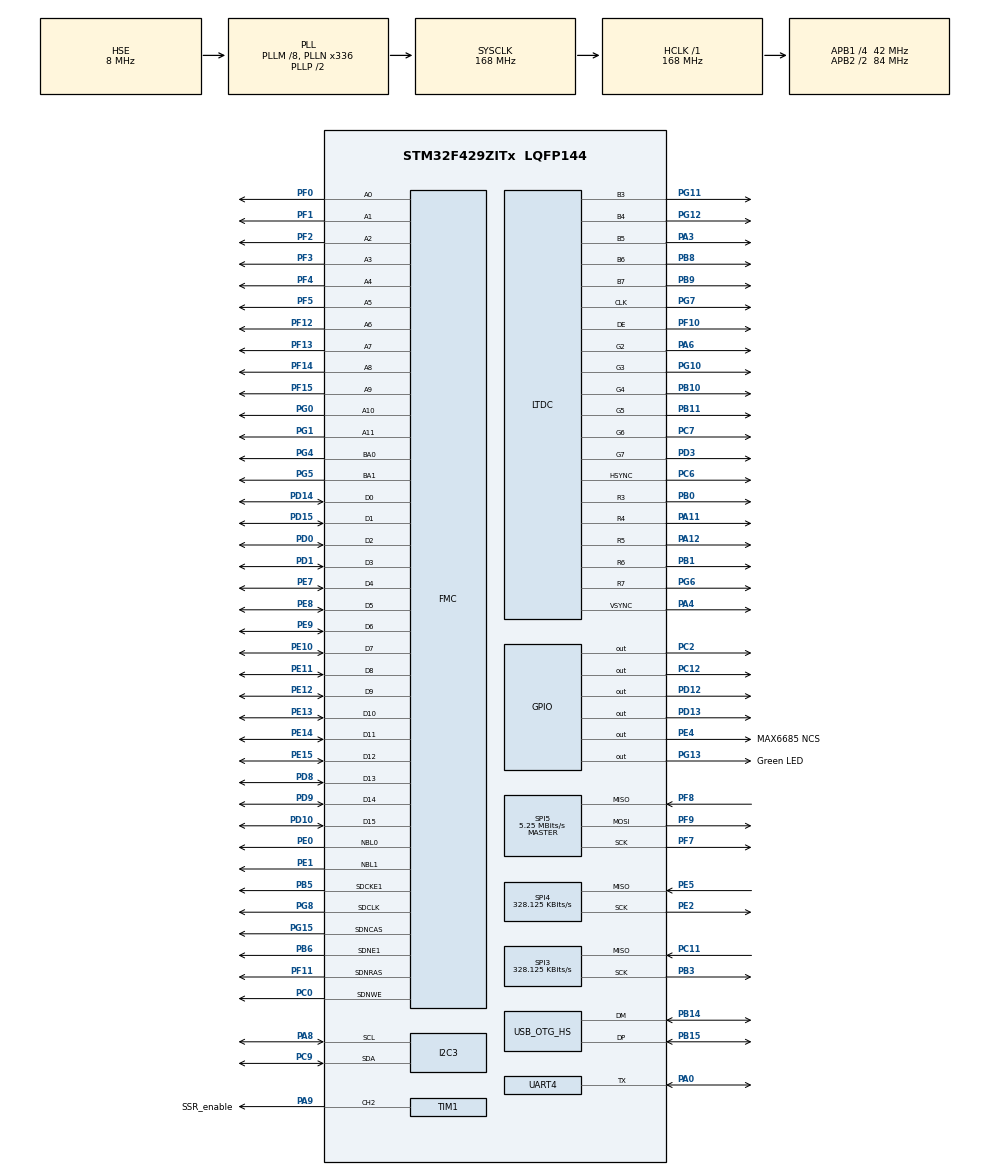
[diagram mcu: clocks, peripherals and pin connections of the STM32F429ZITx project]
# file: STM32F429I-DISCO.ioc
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PA11.GPIO_Speed=GPIO_SPEED_FREQ_HIGH
SH.FMC_D7_DA7.0=FMC_D7,sd-16b-d1
VP_SYS_VS_tim6.Mode=TIM6
SPI3.Direction=SPI_DIRECTION_2LINES_RXONLY
SPI4.VirtualType=VM_MASTER
SPI3.VirtualType=VM_MASTER
FMC.RCDDelay1=2
FMC.SDClockPeriod1=FMC_SDRAM_CLOCK_PERIOD_2
SH.FMC_A0.0=FMC_A0,12b-sda1
PB10.Mode=RGB565
NVIC.TIM6_DAC_IRQn=true\:0\:0\:false\:false\:true\:false\:false\:true
PG4.Signal=FMC_A14_BA0
PG8.Signal=FMC_SDCLK
PC12.Signal=GPIO_Output
PG0.Signal=FMC_A10
FMC.LoadToActiveDelay1=2
SH.FMC_D5_DA5.0=FMC_D5,sd-16b-d1
PA3.GPIO_Speed=GPIO_SPEED_FREQ_HIGH
PD3.GPIO_Speed=GPIO_SPEED_FREQ_HIGH
PG6.Mode=RGB565
PG13.Signal=GPIO_Output
RCC.SYSCLKSource=RCC_SYSCLKSOURCE_PLLCLK
PB11.GPIO_Speed=GPIO_SPEED_FREQ_HIGH
SH.FMC_A15_BA1.0=FMC_BA1,FourSdramBanks1
SH.FMC_D9_DA9.0=FMC_D9,sd-16b-d1
PA4.Mode=RGB565
PF7.Signal=SPI5_SCK
NVIC.DMA2D_IRQn=true\:5\:0\:true\:false\:true\:true\:true\:true
SH.FMC_SDNWE.0=FMC_SDNWE,12b-sda1
SH.FMC_D11_DA11.0=FMC_D11,sd-16b-d1
PE2.Mode=RX_Only_Simplex_Unidirect_Master
RCC.APB2TimFreq_Value=168000000
PB6.Signal=FMC_SDNE1
PC7.Signal=LTDC_G6
PH1/OSC_OUT.Signal=RCC_OSC_OUT
PB6.Mode=SdramChipSelect2_1
PD0.Signal=FMC_D2_DA2
PD8.Signal=FMC_D13_DA13
PE5.Signal=SPI4_MISO
PE1.Signal=FMC_NBL1
I2C3.Analog_Filter=I2C_ANALOGFILTER_DISABLE
PB3.Mode=RX_Only_Simplex_Unidirect_Master
FMC.SelfRefreshTime1=4
LTDC.PixelFormat_L0=LTDC_PIXEL_FORMAT_RGB565
PE9.Signal=FMC_D6_DA6
PB1.GPIO_Speed=GPIO_SPEED_FREQ_HIGH
SH.FMC_A2.0=FMC_A2,12b-sda1
PB14.Mode=Device_Only_FS
STMicroelectronics.X-CUBE-TOUCHGFX.4.16.1.tgfx_display_interface=disp_ltdc
PE4.GPIO_Label=MAX6685 NCS
PC9.Mode=I2C
PE2.Signal=SPI4_SCK
PF8.Mode=Full_Duplex_Master
PA8.Signal=I2C3_SCL
SH.FMC_D1_DA1.0=FMC_D1,sd-16b-d1
PF3.Signal=FMC_A3
PD3.Mode=RGB565
PE10.Signal=FMC_D7_DA7
LTDC.HSync=10
Mcu.Package=LQFP144
PB9.Signal=LTDC_B7
PB1.Signal=LTDC_R6
NVIC.TimeBase=TIM6_DAC_IRQn
SPI3.Mode=SPI_MODE_MASTER
PD12.Signal=GPIO_Output
STMicroelectronics.X-CUBE-TOUCHGFX.4.16.1.ApplicationCcGraphicsJjApplication=TouchGFXOoGenerator
NVIC.TimeBaseIP=TIM6
FMC.WriteRecoveryTime1=3
PC11.Mode=RX_Only_Simplex_Unidirect_Master
SH.FMC_A1.0=FMC_A1,12b-sda1
SPI5.CalculateBaudRate=5.25 MBits/s
RCC.APB2CLKDivider=RCC_HCLK_DIV2
SH.FMC_SDCLK.0=FMC_SDCLK,12b-sda1
LTDC.VSync=2
PF14.Signal=FMC_A8
RCC.APB1TimFreq_Value=84000000
VP_DMA2D_VS_DMA2D.Mode=DMA2D_Activate
PF10.Mode=RGB565
FMC.RowCycleDelay1=7
PA6.GPIO_Speed=GPIO_SPEED_FREQ_HIGH
PC6.GPIO_Speed=GPIO_SPEED_FREQ_HIGH
PD15.Signal=FMC_D1_DA1
SH.FMC_D3_DA3.0=FMC_D3,sd-16b-d1
SPI5.VirtualType=VM_MASTER
PG6.GPIO_Speed=GPIO_SPEED_FREQ_HIGH
PG12.Signal=LTDC_B4
VP_STMicroelectronics.X-CUBE-TOUCHGFX_VS_GraphicsJjApplication_4.16.1.Mode=GraphicsJjApplication
STMicroelectronics.X-CUBE-TOUCHGFX.4.16.1.tgfx_custom_height=240
SPI4.TIMode=SPI_TIMODE_DISABLE
SH.FMC_A4.0=FMC_A4,12b-sda1
FREERTOS.Tasks01=GUI_Task,24,8192,TouchGFX_Task,As weak,NULL,Dynamic,NULL,NULL
STMicroelectronics.X-CUBE-TOUCHGFX.4.16.1.tgfx_address1=0xd0000000
PG5.Signal=FMC_A15_BA1
PA9.GPIO_Label=SSR_enable
SH.FMC_D10_DA10.0=FMC_D10,sd-16b-d1
PD3.Signal=LTDC_G7
PC6.Signal=LTDC_HSYNC
PC2.Signal=GPIO_Output
PD1.Signal=FMC_D3_DA3
PC0.Signal=FMC_SDNWE
RCC.APB1CLKDivider=RCC_HCLK_DIV4
UART4.VirtualMode=Asynchronous
USB_OTG_HS.VirtualMode-Device_Only_FS=Device_Only_FS
PG13.GPIO_Label=Green LED
PG10.Signal=LTDC_G3
LTDC.ImageWidth_L0=240
PD10.Signal=FMC_D15_DA15
PA3.Mode=RGB565
TIM1.AutoReloadPreload=TIM_AUTORELOAD_PRELOAD_ENABLE
SH.FMC_A3.0=FMC_A3,12b-sda1
FMC.CASLatency1=FMC_SDRAM_CAS_LATENCY_3
PB11.Mode=RGB565
FREERTOS.configMAX_PRIORITIES=56
SH.FMC_D15_DA15.0=FMC_D15,sd-16b-d1
PC6.Mode=RGB565
PA9.Signal=S_TIM1_CH2
TIM1.Channel-PWM\ Generation2\ CH2=TIM_CHANNEL_2
PA0/WKUP.Mode=Half_duplex(single_wire_mode)
PB10.Signal=LTDC_G4
PB14.Signal=USB_OTG_HS_DM
PE2.GPIO_PuPd=GPIO_PULLDOWN
SH.FMC_A6.0=FMC_A6,12b-sda1
PE14.Signal=FMC_D11_DA11
LTDC.Blue_L0=0
PE15.Signal=FMC_D12_DA12
PE8.Signal=FMC_D5_DA5
PF13.Signal=FMC_A7
SH.FMC_SDNCAS.0=FMC_SDNCAS,12b-sda1
PA4.Signal=LTDC_VSYNC
PB5.Signal=FMC_SDCKE1
SH.FMC_A5.0=FMC_A5,12b-sda1
PG11.Mode=RGB565
LTDC.Alpha_L0=255
PA11.Signal=LTDC_R4
ProjectManager.HeapSize=0xB00
PB1.Mode=RGB565
PG12.GPIO_Speed=GPIO_SPEED_FREQ_HIGH
PF9.Signal=SPI5_MOSI
NVIC.PriorityGroup=NVIC_PRIORITYGROUP_4
PB8.Mode=RGB565
PA8.Mode=I2C
PF4.Signal=FMC_A4
PB0.Signal=LTDC_R3
Mcu.Family=STM32F4
LTDC.BlendingFactor1_L0=LTDC_BLENDING_FACTOR1_CA
NVIC.OTG_HS_IRQn=true\:5\:0\:false\:false\:true\:true\:false\:true
PA6.Mode=RGB565
SH.FMC_A8.0=FMC_A8,12b-sda1
VP_USB_DEVICE_VS_USB_DEVICE_CDC_HS.Mode=CDC_HS
RCC.CortexFreq_Value=168000000
PG6.Signal=LTDC_R7
PB10.GPIO_Speed=GPIO_SPEED_FREQ_HIGH
RCC.PLLSAIDivR=RCC_PLLSAIDIVR_8
SH.FMC_D14_DA14.0=FMC_D14,sd-16b-d1
TIM1.RepetitionCounter=255
LTDC.HBP=20
STMicroelectronics.X-CUBE-TOUCHGFX.4.16.1.tgfx_buffering_strategy=Double
SPI4.Direction=SPI_DIRECTION_2LINES_RXONLY
SH.FMC_NBL0.0=FMC_NBL0,Sd2ByteEnable1
SH.FMC_D6_DA6.0=FMC_D6,sd-16b-d1
PA11.Mode=RGB565
PA0/WKUP.Signal=UART4_TX
PC2.GPIO_Speed=GPIO_SPEED_FREQ_HIGH
SH.FMC_A14_BA0.0=FMC_BA0,FourSdramBanks1
SH.FMC_A11.0=FMC_A11,12b-sda1
PB11.Signal=LTDC_G5
PB15.Signal=USB_OTG_HS_DP
STMicroelectronics.X-CUBE-TOUCHGFX.4.16.1.tgfx_location=Allocate
PG11.Signal=LTDC_B3
PG15.Signal=FMC_SDNCAS
ProjectManager.StackSize=0xA00
VP_FREERTOS_VS_CMSIS_V2.Mode=CMSIS_V2
PD13.Signal=GPIO_Output
PC11.GPIO_PuPd=GPIO_PULLDOWN
SH.FMC_A7.0=FMC_A7,12b-sda1
PA12.Signal=LTDC_R5
TIM1.Prescaler=1200
SPI4.Mode=SPI_MODE_MASTER
PE5.GPIO_PuPd=GPIO_PULLDOWN
SPI3.CLKPolarity=SPI_POLARITY_LOW
PH0/OSC_IN.Mode=HSE-External-Oscillator
RCC.HCLKFreq_Value=168000000
SH.FMC_NBL1.0=FMC_NBL1,Sd2ByteEnable1
LTDC.WindowX1_L0=240
PF12.Signal=FMC_A6
SPI5.CLKPolarity=SPI_POLARITY_LOW
USB_DEVICE.VirtualMode-CDC_HS=Cdc
SH.FMC_A10.0=FMC_A10,12b-sda1
RCC.AHBFreq_Value=168000000
SPI3.DataSize=SPI_DATASIZE_16BIT
RCC.HSE_VALUE=8000000
USB_OTG_HS.lpm_enable-Device_Only_FS=DISABLE
SH.FMC_D8_DA8.0=FMC_D8,sd-16b-d1
FMC.ExitSelfRefreshDelay1=7
FMC.RPDelay1=2
PA4.GPIO_Speed=GPIO_SPEED_FREQ_HIGH
SH.FMC_D2_DA2.0=FMC_D2,sd-16b-d1
PG11.GPIO_Speed=GPIO_SPEED_FREQ_HIGH
PB3.GPIO_PuPd=GPIO_PULLDOWN
PF9.Mode=Full_Duplex_Master
PE13.Signal=FMC_D10_DA10
PF11.Signal=FMC_SDNRAS
PB5.Mode=SdramChipSelect2_1
LTDC.HFP=10
LTDC.BlendingFactor2_L0=LTDC_BLENDING_FACTOR2_CA
FMC.ReadPipeDelay1=FMC_SDRAM_RPIPE_DELAY_1
SH.FMC_SDNRAS.0=FMC_SDNRAS,12b-sda1
DMA2D.ColorMode=DMA2D_OUTPUT_RGB565
LTDC.ActiveW=240
PH1/OSC_OUT.Mode=HSE-External-Oscillator
PE4.Signal=GPIO_Output
SPI4.BaudRatePrescaler=SPI_BAUDRATEPRESCALER_256
FREERTOS.configTOTAL_HEAP_SIZE=65536
SPI5.BaudRatePrescaler=SPI_BAUDRATEPRESCALER_16
PA6.Signal=LTDC_G2
SH.FMC_D0_DA0.0=FMC_D0,sd-16b-d1
TIM1.Pulse-PWM\ Generation2\ CH2=12000
SH.FMC_A9.0=FMC_A9,12b-sda1
USB_DEVICE.CLASS_NAME_HS=CDC
PF8.Signal=SPI5_MISO
SH.FMC_D4_DA4.0=FMC_D4,sd-16b-d1
RCC.PLLSAIN=192
PF5.Signal=FMC_A5
RCC.PLLSAIR=4
USB_DEVICE.VirtualModeHS=Cdc_HS
PB9.GPIO_Speed=GPIO_SPEED_FREQ_HIGH
PF0.Signal=FMC_A0
PE7.Signal=FMC_D4_DA4
USB_OTG_HS.dma_enable-Device_Only_FS=DISABLE
PA12.GPIO_Speed=GPIO_SPEED_FREQ_HIGH
STMicroelectronics.X-CUBE-TOUCHGFX.4.16.1.tgfx_vsync=vsync_ltdc
PA3.Signal=LTDC_B5
NVIC.LTDC_IRQn=true\:5\:0\:true\:false\:true\:true\:true\:true
LTDC.VFP=4
PD12.GPIO_Speed=GPIO_SPEED_FREQ_HIGH
LTDC.WindowY1_L0=320
PG7.Signal=LTDC_CLK
SPI4.DataSize=SPI_DATASIZE_16BIT
PG1.Signal=FMC_A11
PC11.Signal=SPI3_MISO
PF10.GPIO_Speed=GPIO_SPEED_FREQ_HIGH
PG10.Mode=RGB565
USB_OTG_HS.Sof_enable-Device_Only_FS=DISABLE
PD9.Signal=FMC_D14_DA14
FREERTOS.configUSE_APPLICATION_TASK_TAG=1
PA9.GPIO_PuPd=GPIO_PULLDOWN
PG10.GPIO_Speed=GPIO_SPEED_FREQ_HIGH
SPI5.Mode=SPI_MODE_MASTER
TIM1.ClockDivision=TIM_CLOCKDIVISION_DIV4
USB_OTG_HS.low_power_enable-Device_Only_FS=DISABLE
PB0.GPIO_Speed=GPIO_SPEED_FREQ_HIGH
PF7.Mode=Full_Duplex_Master
STMicroelectronics.X-CUBE-TOUCHGFX.4.16.1.tgfx_hardware_accelerator=dma_2d
ProjectManager.TargetToolchain=STM32CubeIDE
SH.FMC_D13_DA13.0=FMC_D13,sd-16b-d1
LTDC.ActiveH=320
PB9.Mode=RGB565
PF2.Signal=FMC_A2
PE11.Signal=FMC_D8_DA8
PG7.Mode=RGB565
RCC.LSE_VALUE=32768
PB0.Mode=RGB565
board=custom
PG12.Mode=RGB565
SPI3.CLKPhase=SPI_PHASE_1EDGE
USB_OTG_HS.use_dedicated_ep1-Device_Only_FS=DISABLE
PC7.GPIO_Speed=GPIO_SPEED_FREQ_HIGH
RCC.VCOOutputFreq_Value=336000000
PB15.Mode=Device_Only_FS
NVIC.OTG_HS_EP1_OUT_IRQn=true\:5\:0\:false\:false\:true\:true\:false\:true
PH0/OSC_IN.Signal=RCC_OSC_IN
PG7.GPIO_Speed=GPIO_SPEED_FREQ_HIGH
RCC.APB2Freq_Value=84000000
SPI3.CalculateBaudRate=328.125 KBits/s
LTDC.Layers=0
SH.S_TIM1_CH2.0=TIM1_CH2,PWM Generation2 CH2
PF10.Signal=LTDC_DE
PE5.Mode=RX_Only_Simplex_Unidirect_Master
SPI3.BaudRatePrescaler=SPI_BAUDRATEPRESCALER_128
SH.FMC_D12_DA12.0=FMC_D12,sd-16b-d1
PF15.Signal=FMC_A9
SPI4.CalculateBaudRate=328.125 KBits/s
PF1.Signal=FMC_A1
Mcu.Name=STM32F429ZITx
PE0.Signal=FMC_NBL0
PE12.Signal=FMC_D9_DA9
NVIC.OTG_HS_EP1_IN_IRQn=true\:5\:0\:false\:false\:true\:true\:false\:true
PD14.Signal=FMC_D0_DA0
RCC.48MHZClocksFreq_Value=48000000
PB3.Signal=SPI3_SCK
RCC.SYSCLKFreq_VALUE=168000000
PA12.Mode=RGB565
SPI5.CRCCalculation=SPI_CRCCALCULATION_DISABLE
RCC.HSI_VALUE=16000000
RCC.PLLQ=7
RCC.PLLM=8
RCC.PLLN=336
PB8.Signal=LTDC_B6
PC9.Signal=I2C3_SDA
PC7.Mode=RGB565
RCC.APB1Freq_Value=42000000
PB8.GPIO_Speed=GPIO_SPEED_FREQ_HIGH
VP_CRC_VS_CRC.Mode=CRC_Activate
LTDC.ImageHeight_L0=320
TIM1.TIM_MasterSlaveMode=TIM_MASTERSLAVEMODE_ENABLE
SPI5.Direction=SPI_DIRECTION_2LINES

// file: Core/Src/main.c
/* USER CODE BEGIN Header */
/**
  ******************************************************************************
  * @file           : main.c
  * @brief          : Main program body
  ******************************************************************************
  * @attention
  *
  * <h2><center>&copy; Copyright (c) 2020 STMicroelectronics.
  * All rights reserved.</center></h2>
  *
  * This software component is licensed by ST under Ultimate Liberty license
  * SLA0044, the "License"; You may not use this file except in compliance with
  * the License. You may obtain a copy of the License at:
  *                             www.st.com/SLA0044
  *
  ******************************************************************************
  */
/* USER CODE END Header */
#include "main.h"
#include "cmsis_os.h"
#include "app_touchgfx.h"
#include "usb_device.h"

/* USER CODE BEGIN Includes */
#include <stdio.h>
#include "Components/ili9341/ili9341.h"
#include "common.h"
/* USER CODE END Includes */

/* USER CODE BEGIN PD */
#define REFRESH_COUNT           ((uint32_t)1386)   /* SDRAM refresh counter */
#define SDRAM_TIMEOUT           ((uint32_t)0xFFFF)

/**
  * @brief  FMC SDRAM Mode definition register defines
  */
#define SDRAM_MODEREG_BURST_LENGTH_1             ((uint16_t)0x0000)
#define SDRAM_MODEREG_BURST_LENGTH_2             ((uint16_t)0x0001)
#define SDRAM_MODEREG_BURST_LENGTH_4             ((uint16_t)0x0002)
#define SDRAM_MODEREG_BURST_LENGTH_8             ((uint16_t)0x0004)
#define SDRAM_MODEREG_BURST_TYPE_SEQUENTIAL      ((uint16_t)0x0000)
#define SDRAM_MODEREG_BURST_TYPE_INTERLEAVED     ((uint16_t)0x0008)
#define SDRAM_MODEREG_CAS_LATENCY_2              ((uint16_t)0x0020)
#define SDRAM_MODEREG_CAS_LATENCY_3              ((uint16_t)0x0030)
#define SDRAM_MODEREG_OPERATING_MODE_STANDARD    ((uint16_t)0x0000)
#define SDRAM_MODEREG_WRITEBURST_MODE_PROGRAMMED ((uint16_t)0x0000)
#define SDRAM_MODEREG_WRITEBURST_MODE_SINGLE     ((uint16_t)0x0200)

#define I2C3_TIMEOUT_MAX                    0x3000 /*<! The value of the maximal timeout for I2C waiting loops */
#define SPI5_TIMEOUT_MAX                    0x1000
/* USER CODE END PD */

CRC_HandleTypeDef hcrc;

DMA2D_HandleTypeDef hdma2d;

I2C_HandleTypeDef hi2c3;

LTDC_HandleTypeDef hltdc;

SPI_HandleTypeDef hspi3;
SPI_HandleTypeDef hspi4;
SPI_HandleTypeDef hspi5;

TIM_HandleTypeDef htim1;

UART_HandleTypeDef huart4;

SDRAM_HandleTypeDef hsdram1;

/* Definitions for GUI_Task */
osThreadId_t GUI_TaskHandle;
const osThreadAttr_t GUI_Task_attributes = {
  .name = "GUI_Task",
  .stack_size = 8192 * 4,
  .priority = (osPriority_t) osPriorityNormal,
};
/* USER CODE BEGIN PV */
osThreadId_t App_TaskHandle;
const osThreadAttr_t App_Task_attributes = {
  .name = "App_Task",
  .stack_size = 8192 * 1,
  .priority = (osPriority_t) osPriorityNormal,
};

/* USER CODE END PV */

void SystemClock_Config(void);
static void MX_GPIO_Init(void);
static void MX_CRC_Init(void);
static void MX_I2C3_Init(void);
static void MX_SPI5_Init(void);
static void MX_FMC_Init(void);
static void MX_LTDC_Init(void);
static void MX_DMA2D_Init(void);
static void MX_SPI4_Init(void);
static void MX_TIM1_Init(void);
static void MX_SPI3_Init(void);
static void MX_UART4_Init(void);
void TouchGFX_Task(void *argument);

/* USER CODE BEGIN PFP */
void App_Task(void *argument);

osMessageQueueId_t TempQueue;
osEventFlagsId_t msgFlags;

static void BSP_SDRAM_Initialization_Sequence(SDRAM_HandleTypeDef *hsdram, FMC_SDRAM_CommandTypeDef *Command);

static uint8_t            I2C3_ReadData(uint8_t Addr, uint8_t Reg);
static void               I2C3_WriteData(uint8_t Addr, uint8_t Reg, uint8_t Value);
static uint8_t            I2C3_ReadBuffer(uint8_t Addr, uint8_t Reg, uint8_t *pBuffer, uint16_t Length);

/* SPIx bus function */
static void               SPI5_Write(uint16_t Value);
static uint32_t           SPI5_Read(uint8_t ReadSize);
static void               SPI5_Error(void);

/* Link function for LCD peripheral */
void                      LCD_IO_Init(void);
void                      LCD_IO_WriteData(uint16_t RegValue);
void                      LCD_IO_WriteReg(uint8_t Reg);
uint32_t                  LCD_IO_ReadData(uint16_t RegValue, uint8_t ReadSize);
void                      LCD_Delay(uint32_t delay);

/* IOExpander IO functions */
void                      IOE_Init(void);
void                      IOE_ITConfig(void);
void                      IOE_Delay(uint32_t Delay);
void                      IOE_Write(uint8_t Addr, uint8_t Reg, uint8_t Value);
uint8_t                   IOE_Read(uint8_t Addr, uint8_t Reg);
uint16_t                  IOE_ReadMultiple(uint8_t Addr, uint8_t Reg, uint8_t *pBuffer, uint16_t Length);

/* USER CODE END PFP */

/* USER CODE BEGIN 0 */
static LCD_DrvTypeDef* LcdDrv;

uint32_t I2c3Timeout = I2C3_TIMEOUT_MAX; /*<! Value of Timeout when I2C communication fails */
uint32_t Spi5Timeout = SPI5_TIMEOUT_MAX; /*<! Value of Timeout when SPI communication fails */
/* USER CODE END 0 */

int main(void)
{

  /* MCU Configuration--------------------------------------------------------*/

  /* Reset of all peripherals, Initializes the Flash interface and the Systick. */
  HAL_Init();

  /* Configure the system clock */
  SystemClock_Config();

  /* Initialize all configured peripherals */
  MX_GPIO_Init();
  MX_CRC_Init();
  MX_I2C3_Init();
  MX_SPI5_Init();
  MX_FMC_Init();
  MX_LTDC_Init();
  MX_DMA2D_Init();
  MX_SPI4_Init();
  MX_TIM1_Init();
  MX_SPI3_Init();
  MX_UART4_Init();
  MX_TouchGFX_Init();
  /* USER CODE BEGIN 2 */
  TempQueue = osMessageQueueNew(1, sizeof(float), NULL);
  msgFlags =  osEventFlagsNew(NULL);

  HAL_GPIO_WritePin(GPIOE, GPIO_PIN_4, GPIO_PIN_SET);
  /* USER CODE END 2 */

  /* Init scheduler */
  osKernelInitialize();

  /* Create the thread(s) */
  /* creation of GUI_Task */
  GUI_TaskHandle = osThreadNew(TouchGFX_Task, NULL, &GUI_Task_attributes);

  /* USER CODE BEGIN RTOS_THREADS */
  /* add threads, ... */
  App_TaskHandle = osThreadNew(App_Task, NULL, &App_Task_attributes);
  /* USER CODE END RTOS_THREADS */

  /* Start scheduler */
  osKernelStart();

  /* We should never get here as control is now taken by the scheduler */
  /* Infinite loop */
  while (1)
  {

  }
}

void SystemClock_Config(void)
{
  RCC_OscInitTypeDef RCC_OscInitStruct = {0};
  RCC_ClkInitTypeDef RCC_ClkInitStruct = {0};
  RCC_PeriphCLKInitTypeDef PeriphClkInitStruct = {0};

  /** Configure the main internal regulator output voltage
  */
  __HAL_RCC_PWR_CLK_ENABLE();
  __HAL_PWR_VOLTAGESCALING_CONFIG(PWR_REGULATOR_VOLTAGE_SCALE1);
  /** Initializes the RCC Oscillators according to the specified parameters
  * in the RCC_OscInitTypeDef structure.
  */
  RCC_OscInitStruct.OscillatorType = RCC_OSCILLATORTYPE_HSE;
  RCC_OscInitStruct.HSEState = RCC_HSE_ON;
  RCC_OscInitStruct.PLL.PLLState = RCC_PLL_ON;
  RCC_OscInitStruct.PLL.PLLSource = RCC_PLLSOURCE_HSE;
  RCC_OscInitStruct.PLL.PLLM = 8;
  RCC_OscInitStruct.PLL.PLLN = 336;
  RCC_OscInitStruct.PLL.PLLP = RCC_PLLP_DIV2;
  RCC_OscInitStruct.PLL.PLLQ = 7;
  if (HAL_RCC_OscConfig(&RCC_OscInitStruct) != HAL_OK)
  {
    Error_Handler();
  }
  /** Initializes the CPU, AHB and APB buses clocks
  */
  RCC_ClkInitStruct.ClockType = RCC_CLOCKTYPE_HCLK|RCC_CLOCKTYPE_SYSCLK
                              |RCC_CLOCKTYPE_PCLK1|RCC_CLOCKTYPE_PCLK2;
  RCC_ClkInitStruct.SYSCLKSource = RCC_SYSCLKSOURCE_PLLCLK;
  RCC_ClkInitStruct.AHBCLKDivider = RCC_SYSCLK_DIV1;
  RCC_ClkInitStruct.APB1CLKDivider = RCC_HCLK_DIV4;
  RCC_ClkInitStruct.APB2CLKDivider = RCC_HCLK_DIV2;

  if (HAL_RCC_ClockConfig(&RCC_ClkInitStruct, FLASH_LATENCY_5) != HAL_OK)
  {
    Error_Handler();
  }
  PeriphClkInitStruct.PeriphClockSelection = RCC_PERIPHCLK_LTDC;
  PeriphClkInitStruct.PLLSAI.PLLSAIN = 192;
  PeriphClkInitStruct.PLLSAI.PLLSAIR = 4;
  PeriphClkInitStruct.PLLSAIDivR = RCC_PLLSAIDIVR_8;
  if (HAL_RCCEx_PeriphCLKConfig(&PeriphClkInitStruct) != HAL_OK)
  {
    Error_Handler();
  }
}

static void MX_CRC_Init(void)
{

  hcrc.Instance = CRC;
  if (HAL_CRC_Init(&hcrc) != HAL_OK)
  {
    Error_Handler();
  }

}

static void MX_DMA2D_Init(void)
{

  hdma2d.Instance = DMA2D;
  hdma2d.Init.Mode = DMA2D_M2M;
  hdma2d.Init.ColorMode = DMA2D_OUTPUT_RGB565;
  hdma2d.Init.OutputOffset = 0;
  hdma2d.LayerCfg[1].InputOffset = 0;
  hdma2d.LayerCfg[1].InputColorMode = DMA2D_INPUT_RGB565;
  hdma2d.LayerCfg[1].AlphaMode = DMA2D_NO_MODIF_ALPHA;
  hdma2d.LayerCfg[1].InputAlpha = 0;
  if (HAL_DMA2D_Init(&hdma2d) != HAL_OK)
  {
    Error_Handler();
  }
  if (HAL_DMA2D_ConfigLayer(&hdma2d, 1) != HAL_OK)
  {
    Error_Handler();
  }

}

static void MX_I2C3_Init(void)
{

  hi2c3.Instance = I2C3;
  hi2c3.Init.ClockSpeed = 100000;
  hi2c3.Init.DutyCycle = I2C_DUTYCYCLE_2;
  hi2c3.Init.OwnAddress1 = 0;
  hi2c3.Init.AddressingMode = I2C_ADDRESSINGMODE_7BIT;
  hi2c3.Init.DualAddressMode = I2C_DUALADDRESS_DISABLE;
  hi2c3.Init.OwnAddress2 = 0;
  hi2c3.Init.GeneralCallMode = I2C_GENERALCALL_DISABLE;
  hi2c3.Init.NoStretchMode = I2C_NOSTRETCH_DISABLE;
  if (HAL_I2C_Init(&hi2c3) != HAL_OK)
  {
    Error_Handler();
  }
  /** Configure Analogue filter
  */
  if (HAL_I2CEx_ConfigAnalogFilter(&hi2c3, I2C_ANALOGFILTER_DISABLE) != HAL_OK)
  {
    Error_Handler();
  }
  /** Configure Digital filter
  */
  if (HAL_I2CEx_ConfigDigitalFilter(&hi2c3, 0) != HAL_OK)
  {
    Error_Handler();
  }

}

static void MX_LTDC_Init(void)
{

  LTDC_LayerCfgTypeDef pLayerCfg = {0};

  hltdc.Instance = LTDC;
  hltdc.Init.HSPolarity = LTDC_HSPOLARITY_AL;
  hltdc.Init.VSPolarity = LTDC_VSPOLARITY_AL;
  hltdc.Init.DEPolarity = LTDC_DEPOLARITY_AL;
  hltdc.Init.PCPolarity = LTDC_PCPOLARITY_IPC;
  hltdc.Init.HorizontalSync = 9;
  hltdc.Init.VerticalSync = 1;
  hltdc.Init.AccumulatedHBP = 29;
  hltdc.Init.AccumulatedVBP = 3;
  hltdc.Init.AccumulatedActiveW = 269;
  hltdc.Init.AccumulatedActiveH = 323;
  hltdc.Init.TotalWidth = 279;
  hltdc.Init.TotalHeigh = 327;
  hltdc.Init.Backcolor.Blue = 0;
  hltdc.Init.Backcolor.Green = 0;
  hltdc.Init.Backcolor.Red = 0;
  if (HAL_LTDC_Init(&hltdc) != HAL_OK)
  {
    Error_Handler();
  }
  pLayerCfg.WindowX0 = 0;
  pLayerCfg.WindowX1 = 240;
  pLayerCfg.WindowY0 = 0;
  pLayerCfg.WindowY1 = 320;
  pLayerCfg.PixelFormat = LTDC_PIXEL_FORMAT_RGB565;
  pLayerCfg.Alpha = 255;
  pLayerCfg.Alpha0 = 0;
  pLayerCfg.BlendingFactor1 = LTDC_BLENDING_FACTOR1_CA;
  pLayerCfg.BlendingFactor2 = LTDC_BLENDING_FACTOR2_CA;
  pLayerCfg.FBStartAdress = 0;
  pLayerCfg.ImageWidth = 240;
  pLayerCfg.ImageHeight = 320;
  pLayerCfg.Backcolor.Blue = 0;
  pLayerCfg.Backcolor.Green = 0;
  pLayerCfg.Backcolor.Red = 0;
  if (HAL_LTDC_ConfigLayer(&hltdc, &pLayerCfg, 0) != HAL_OK)
  {
    Error_Handler();
  }
  /* USER CODE BEGIN LTDC_Init 2 */
    /*Select the device */
  LcdDrv = &ili9341_drv;
  /* LCD Init */
  LcdDrv->Init();

  LcdDrv->DisplayOff();
  /* USER CODE END LTDC_Init 2 */

}

static void MX_SPI3_Init(void)
{

  /* SPI3 parameter configuration*/
  hspi3.Instance = SPI3;
  hspi3.Init.Mode = SPI_MODE_MASTER;
  hspi3.Init.Direction = SPI_DIRECTION_2LINES_RXONLY;
  hspi3.Init.DataSize = SPI_DATASIZE_16BIT;
  hspi3.Init.CLKPolarity = SPI_POLARITY_LOW;
  hspi3.Init.CLKPhase = SPI_PHASE_1EDGE;
  hspi3.Init.NSS = SPI_NSS_SOFT;
  hspi3.Init.BaudRatePrescaler = SPI_BAUDRATEPRESCALER_128;
  hspi3.Init.FirstBit = SPI_FIRSTBIT_MSB;
  hspi3.Init.TIMode = SPI_TIMODE_DISABLE;
  hspi3.Init.CRCCalculation = SPI_CRCCALCULATION_DISABLE;
  hspi3.Init.CRCPolynomial = 10;
  if (HAL_SPI_Init(&hspi3) != HAL_OK)
  {
    Error_Handler();
  }

}

static void MX_SPI4_Init(void)
{

  /* SPI4 parameter configuration*/
  hspi4.Instance = SPI4;
  hspi4.Init.Mode = SPI_MODE_MASTER;
  hspi4.Init.Direction = SPI_DIRECTION_2LINES_RXONLY;
  hspi4.Init.DataSize = SPI_DATASIZE_16BIT;
  hspi4.Init.CLKPolarity = SPI_POLARITY_LOW;
  hspi4.Init.CLKPhase = SPI_PHASE_1EDGE;
  hspi4.Init.NSS = SPI_NSS_SOFT;
  hspi4.Init.BaudRatePrescaler = SPI_BAUDRATEPRESCALER_256;
  hspi4.Init.FirstBit = SPI_FIRSTBIT_MSB;
  hspi4.Init.TIMode = SPI_TIMODE_DISABLE;
  hspi4.Init.CRCCalculation = SPI_CRCCALCULATION_DISABLE;
  hspi4.Init.CRCPolynomial = 10;
  if (HAL_SPI_Init(&hspi4) != HAL_OK)
  {
    Error_Handler();
  }

}

static void MX_SPI5_Init(void)
{

  /* SPI5 parameter configuration*/
  hspi5.Instance = SPI5;
  hspi5.Init.Mode = SPI_MODE_MASTER;
  hspi5.Init.Direction = SPI_DIRECTION_2LINES;
  hspi5.Init.DataSize = SPI_DATASIZE_8BIT;
  hspi5.Init.CLKPolarity = SPI_POLARITY_LOW;
  hspi5.Init.CLKPhase = SPI_PHASE_1EDGE;
  hspi5.Init.NSS = SPI_NSS_SOFT;
  hspi5.Init.BaudRatePrescaler = SPI_BAUDRATEPRESCALER_16;
  hspi5.Init.FirstBit = SPI_FIRSTBIT_MSB;
  hspi5.Init.TIMode = SPI_TIMODE_DISABLE;
  hspi5.Init.CRCCalculation = SPI_CRCCALCULATION_DISABLE;
  hspi5.Init.CRCPolynomial = 10;
  if (HAL_SPI_Init(&hspi5) != HAL_OK)
  {
    Error_Handler();
  }

}

static void MX_TIM1_Init(void)
{

  TIM_MasterConfigTypeDef sMasterConfig = {0};
  TIM_OC_InitTypeDef sConfigOC = {0};
  TIM_BreakDeadTimeConfigTypeDef sBreakDeadTimeConfig = {0};

  htim1.Instance = TIM1;
  htim1.Init.Prescaler = 1200;
  htim1.Init.CounterMode = TIM_COUNTERMODE_UP;
  htim1.Init.Period = 65535;
  htim1.Init.ClockDivision = TIM_CLOCKDIVISION_DIV4;
  htim1.Init.RepetitionCounter = 255;
  htim1.Init.AutoReloadPreload = TIM_AUTORELOAD_PRELOAD_ENABLE;
  if (HAL_TIM_PWM_Init(&htim1) != HAL_OK)
  {
    Error_Handler();
  }
  sMasterConfig.MasterOutputTrigger = TIM_TRGO_RESET;
  sMasterConfig.MasterSlaveMode = TIM_MASTERSLAVEMODE_ENABLE;
  if (HAL_TIMEx_MasterConfigSynchronization(&htim1, &sMasterConfig) != HAL_OK)
  {
    Error_Handler();
  }
  sConfigOC.OCMode = TIM_OCMODE_PWM1;
  sConfigOC.Pulse = 12000;
  sConfigOC.OCPolarity = TIM_OCPOLARITY_HIGH;
  sConfigOC.OCNPolarity = TIM_OCNPOLARITY_HIGH;
  sConfigOC.OCFastMode = TIM_OCFAST_DISABLE;
  sConfigOC.OCIdleState = TIM_OCIDLESTATE_RESET;
  sConfigOC.OCNIdleState = TIM_OCNIDLESTATE_RESET;
  if (HAL_TIM_PWM_ConfigChannel(&htim1, &sConfigOC, TIM_CHANNEL_2) != HAL_OK)
  {
    Error_Handler();
  }
  sBreakDeadTimeConfig.OffStateRunMode = TIM_OSSR_DISABLE;
  sBreakDeadTimeConfig.OffStateIDLEMode = TIM_OSSI_DISABLE;
  sBreakDeadTimeConfig.LockLevel = TIM_LOCKLEVEL_OFF;
  sBreakDeadTimeConfig.DeadTime = 0;
  sBreakDeadTimeConfig.BreakState = TIM_BREAK_DISABLE;
  sBreakDeadTimeConfig.BreakPolarity = TIM_BREAKPOLARITY_HIGH;
  sBreakDeadTimeConfig.AutomaticOutput = TIM_AUTOMATICOUTPUT_DISABLE;
  if (HAL_TIMEx_ConfigBreakDeadTime(&htim1, &sBreakDeadTimeConfig) != HAL_OK)
  {
    Error_Handler();
  }
  HAL_TIM_MspPostInit(&htim1);

}

static void MX_UART4_Init(void)
{

  huart4.Instance = UART4;
  huart4.Init.BaudRate = 115200;
  huart4.Init.WordLength = UART_WORDLENGTH_8B;
  huart4.Init.StopBits = UART_STOPBITS_1;
  huart4.Init.Parity = UART_PARITY_NONE;
  huart4.Init.Mode = UART_MODE_TX_RX;
  huart4.Init.HwFlowCtl = UART_HWCONTROL_NONE;
  huart4.Init.OverSampling = UART_OVERSAMPLING_16;
  if (HAL_HalfDuplex_Init(&huart4) != HAL_OK)
  {
    Error_Handler();
  }

}

/* FMC initialization function */
static void MX_FMC_Init(void)
{

  FMC_SDRAM_TimingTypeDef SdramTiming = {0};

  /** Perform the SDRAM1 memory initialization sequence
  */
  hsdram1.Instance = FMC_SDRAM_DEVICE;
  /* hsdram1.Init */
  hsdram1.Init.SDBank = FMC_SDRAM_BANK2;
  hsdram1.Init.ColumnBitsNumber = FMC_SDRAM_COLUMN_BITS_NUM_8;
  hsdram1.Init.RowBitsNumber = FMC_SDRAM_ROW_BITS_NUM_12;
  hsdram1.Init.MemoryDataWidth = FMC_SDRAM_MEM_BUS_WIDTH_16;
  hsdram1.Init.InternalBankNumber = FMC_SDRAM_INTERN_BANKS_NUM_4;
  hsdram1.Init.CASLatency = FMC_SDRAM_CAS_LATENCY_3;
  hsdram1.Init.WriteProtection = FMC_SDRAM_WRITE_PROTECTION_DISABLE;
  hsdram1.Init.SDClockPeriod = FMC_SDRAM_CLOCK_PERIOD_2;
  hsdram1.Init.ReadBurst = FMC_SDRAM_RBURST_DISABLE;
  hsdram1.Init.ReadPipeDelay = FMC_SDRAM_RPIPE_DELAY_1;
  /* SdramTiming */
  SdramTiming.LoadToActiveDelay = 2;
  SdramTiming.ExitSelfRefreshDelay = 7;
  SdramTiming.SelfRefreshTime = 4;
  SdramTiming.RowCycleDelay = 7;
  SdramTiming.WriteRecoveryTime = 3;
  SdramTiming.RPDelay = 2;
  SdramTiming.RCDDelay = 2;

  if (HAL_SDRAM_Init(&hsdram1, &SdramTiming) != HAL_OK)
  {
    Error_Handler( );
  }

  /* USER CODE BEGIN FMC_Init 2 */

  FMC_SDRAM_CommandTypeDef command;

  /* Program the SDRAM external device */
  BSP_SDRAM_Initialization_Sequence(&hsdram1, &command);
  /* USER CODE END FMC_Init 2 */
}

static void MX_GPIO_Init(void)
{
  GPIO_InitTypeDef GPIO_InitStruct = {0};

  /* GPIO Ports Clock Enable */
  __HAL_RCC_GPIOE_CLK_ENABLE();
  __HAL_RCC_GPIOF_CLK_ENABLE();
  __HAL_RCC_GPIOH_CLK_ENABLE();
  __HAL_RCC_GPIOC_CLK_ENABLE();
  __HAL_RCC_GPIOA_CLK_ENABLE();
  __HAL_RCC_GPIOB_CLK_ENABLE();
  __HAL_RCC_GPIOG_CLK_ENABLE();
  __HAL_RCC_GPIOD_CLK_ENABLE();

  /*Configure GPIO pin Output Level */
  HAL_GPIO_WritePin(MAX6685_NCS_GPIO_Port, MAX6685_NCS_Pin, GPIO_PIN_RESET);

  /*Configure GPIO pin Output Level */
  HAL_GPIO_WritePin(GPIOC, GPIO_PIN_2, GPIO_PIN_RESET);

  /*Configure GPIO pin Output Level */
  HAL_GPIO_WritePin(GPIOD, GPIO_PIN_12|GPIO_PIN_13, GPIO_PIN_RESET);

  /*Configure GPIO pin Output Level */
  HAL_GPIO_WritePin(Green_LED_GPIO_Port, Green_LED_Pin, GPIO_PIN_RESET);

  /*Configure GPIO pin : MAX6685_NCS_Pin */
  GPIO_InitStruct.Pin = MAX6685_NCS_Pin;
  GPIO_InitStruct.Mode = GPIO_MODE_OUTPUT_PP;
  GPIO_InitStruct.Pull = GPIO_NOPULL;
  GPIO_InitStruct.Speed = GPIO_SPEED_FREQ_LOW;
  HAL_GPIO_Init(MAX6685_NCS_GPIO_Port, &GPIO_InitStruct);

  /*Configure GPIO pin : PC2 */
  GPIO_InitStruct.Pin = GPIO_PIN_2;
  GPIO_InitStruct.Mode = GPIO_MODE_OUTPUT_PP;
  GPIO_InitStruct.Pull = GPIO_NOPULL;
  GPIO_InitStruct.Speed = GPIO_SPEED_FREQ_HIGH;
  HAL_GPIO_Init(GPIOC, &GPIO_InitStruct);

  /*Configure GPIO pin : PD12 */
  GPIO_InitStruct.Pin = GPIO_PIN_12;
  GPIO_InitStruct.Mode = GPIO_MODE_OUTPUT_PP;
  GPIO_InitStruct.Pull = GPIO_NOPULL;
  GPIO_InitStruct.Speed = GPIO_SPEED_FREQ_HIGH;
  HAL_GPIO_Init(GPIOD, &GPIO_InitStruct);

  /*Configure GPIO pin : PD13 */
  GPIO_InitStruct.Pin = GPIO_PIN_13;
  GPIO_InitStruct.Mode = GPIO_MODE_OUTPUT_PP;
  GPIO_InitStruct.Pull = GPIO_NOPULL;
  GPIO_InitStruct.Speed = GPIO_SPEED_FREQ_LOW;
  HAL_GPIO_Init(GPIOD, &GPIO_InitStruct);

  /*Configure GPIO pin : Green_LED_Pin */
  GPIO_InitStruct.Pin = Green_LED_Pin;
  GPIO_InitStruct.Mode = GPIO_MODE_OUTPUT_PP;
  GPIO_InitStruct.Pull = GPIO_NOPULL;
  GPIO_InitStruct.Speed = GPIO_SPEED_FREQ_LOW;
  HAL_GPIO_Init(Green_LED_GPIO_Port, &GPIO_InitStruct);

}

/* USER CODE BEGIN 4 */
/**
  * @brief  Perform the SDRAM external memory initialization sequence
  * @param  hsdram: SDRAM handle
  * @param  Command: Pointer to SDRAM command structure
  * @retval None
  */
static void BSP_SDRAM_Initialization_Sequence(SDRAM_HandleTypeDef *hsdram, FMC_SDRAM_CommandTypeDef *Command)
{
 __IO uint32_t tmpmrd =0;

  /* Step 1:  Configure a clock configuration enable command */
  Command->CommandMode             = FMC_SDRAM_CMD_CLK_ENABLE;
  Command->CommandTarget           = FMC_SDRAM_CMD_TARGET_BANK2;
  Command->AutoRefreshNumber       = 1;
  Command->ModeRegisterDefinition  = 0;

  /* Send the command */
  HAL_SDRAM_SendCommand(hsdram, Command, SDRAM_TIMEOUT);

  /* Step 2: Insert 100 us minimum delay */
  /* Inserted delay is equal to 1 ms due to systick time base unit (ms) */
  HAL_Delay(1);

  /* Step 3: Configure a PALL (precharge all) command */
  Command->CommandMode             = FMC_SDRAM_CMD_PALL;
  Command->CommandTarget           = FMC_SDRAM_CMD_TARGET_BANK2;
  Command->AutoRefreshNumber       = 1;
  Command->ModeRegisterDefinition  = 0;

  /* Send the command */
  HAL_SDRAM_SendCommand(hsdram, Command, SDRAM_TIMEOUT);

  /* Step 4: Configure an Auto Refresh command */
  Command->CommandMode             = FMC_SDRAM_CMD_AUTOREFRESH_MODE;
  Command->CommandTarget           = FMC_SDRAM_CMD_TARGET_BANK2;
  Command->AutoRefreshNumber       = 4;
  Command->ModeRegisterDefinition  = 0;

  /* Send the command */
  HAL_SDRAM_SendCommand(hsdram, Command, SDRAM_TIMEOUT);

  /* Step 5: Program the external memory mode register */
  tmpmrd = (uint32_t)SDRAM_MODEREG_BURST_LENGTH_1          |
                     SDRAM_MODEREG_BURST_TYPE_SEQUENTIAL   |
                     SDRAM_MODEREG_CAS_LATENCY_3           |
                     SDRAM_MODEREG_OPERATING_MODE_STANDARD |
                     SDRAM_MODEREG_WRITEBURST_MODE_SINGLE;

  Command->CommandMode             = FMC_SDRAM_CMD_LOAD_MODE;
  Command->CommandTarget           = FMC_SDRAM_CMD_TARGET_BANK2;
  Command->AutoRefreshNumber       = 1;
  Command->ModeRegisterDefinition  = tmpmrd;

  /* Send the command */
  HAL_SDRAM_SendCommand(hsdram, Command, SDRAM_TIMEOUT);

  /* Step 6: Set the refresh rate counter */
  /* Set the device refresh rate */
  HAL_SDRAM_ProgramRefreshRate(hsdram, REFRESH_COUNT);
}

/**
  * @brief  IOE Low Level Initialization.
  */
void IOE_Init(void)
{
  //Dummy function called when initializing to stmpe811 to setup the i2c.
  //This is done with cubmx and is therfore not done here.
}

/**
  * @brief  IOE Low Level Interrupt configuration.
  */
void IOE_ITConfig(void)
{
  //Dummy function called when initializing to stmpe811 to setup interupt for the i2c.
  //The interupt is not used in our case, therefore nothing is done here.
}

/**
  * @brief  IOE Writes single data operation.
  * @param  Addr: I2C Address
  * @param  Reg: Reg Address
  * @param  Value: Data to be written
  */
void IOE_Write(uint8_t Addr, uint8_t Reg, uint8_t Value)
{
  I2C3_WriteData(Addr, Reg, Value);
}

/**
  * @brief  IOE Reads single data.
  * @param  Addr: I2C Address
  * @param  Reg: Reg Address
  * @retval The read data
  */
uint8_t IOE_Read(uint8_t Addr, uint8_t Reg)
{
  return I2C3_ReadData(Addr, Reg);
}

/**
  * @brief  IOE Reads multiple data.
  * @param  Addr: I2C Address
  * @param  Reg: Reg Address
  * @param  pBuffer: pointer to data buffer
  * @param  Length: length of the data
  * @retval 0 if no problems to read multiple data
  */
uint16_t IOE_ReadMultiple(uint8_t Addr, uint8_t Reg, uint8_t *pBuffer, uint16_t Length)
{
 return I2C3_ReadBuffer(Addr, Reg, pBuffer, Length);
}

/**
  * @brief  IOE Delay.
  * @param  Delay in ms
  */
void IOE_Delay(uint32_t Delay)
{
  HAL_Delay(Delay);
}

/**
  * @brief  Writes a value in a register of the device through BUS.
  * @param  Addr: Device address on BUS Bus.
  * @param  Reg: The target register address to write
  * @param  Value: The target register value to be written
  */
static void I2C3_WriteData(uint8_t Addr, uint8_t Reg, uint8_t Value)
{
  HAL_StatusTypeDef status = HAL_OK;

  status = HAL_I2C_Mem_Write(&hi2c3, Addr, (uint16_t)Reg, I2C_MEMADD_SIZE_8BIT, &Value, 1, I2c3Timeout);

  /* Check the communication status */
  if(status != HAL_OK)
  {
    /* Re-Initialize the BUS */
    //I2Cx_Error();
  }
}

/**
  * @brief  Reads a register of the device through BUS.
  * @param  Addr: Device address on BUS Bus.
  * @param  Reg: The target register address to write
  * @retval Data read at register address
  */
static uint8_t I2C3_ReadData(uint8_t Addr, uint8_t Reg)
{
  HAL_StatusTypeDef status = HAL_OK;
  uint8_t value = 0;

  status = HAL_I2C_Mem_Read(&hi2c3, Addr, Reg, I2C_MEMADD_SIZE_8BIT, &value, 1, I2c3Timeout);

  /* Check the communication status */
  if(status != HAL_OK)
  {
    /* Re-Initialize the BUS */
    //I2Cx_Error();

  }
  return value;
}

/**
  * @brief  Reads multiple data on the BUS.
  * @param  Addr: I2C Address
  * @param  Reg: Reg Address
  * @param  pBuffer: pointer to read data buffer
  * @param  Length: length of the data
  * @retval 0 if no problems to read multiple data
  */
static uint8_t I2C3_ReadBuffer(uint8_t Addr, uint8_t Reg, uint8_t *pBuffer, uint16_t Length)
{
  HAL_StatusTypeDef status = HAL_OK;

  status = HAL_I2C_Mem_Read(&hi2c3, Addr, (uint16_t)Reg, I2C_MEMADD_SIZE_8BIT, pBuffer, Length, I2c3Timeout);

  /* Check the communication status */
  if(status == HAL_OK)
  {
    return 0;
  }
  else
  {
    /* Re-Initialize the BUS */
    //I2Cx_Error();

    return 1;
  }
}

/**
  * @brief  Reads 4 bytes from device.
  * @param  ReadSize: Number of bytes to read (max 4 bytes)
  * @retval Value read on the SPI
  */
static uint32_t SPI5_Read(uint8_t ReadSize)
{
  HAL_StatusTypeDef status = HAL_OK;
  uint32_t readvalue;

  status = HAL_SPI_Receive(&hspi5, (uint8_t*) &readvalue, ReadSize, Spi5Timeout);

  /* Check the communication status */
  if(status != HAL_OK)
  {
    /* Re-Initialize the BUS */
    SPI5_Error();
  }

  return readvalue;
}

/**
  * @brief  Writes a byte to device.
  * @param  Value: value to be written
  */
static void SPI5_Write(uint16_t Value)
{
  HAL_StatusTypeDef status = HAL_OK;

  status = HAL_SPI_Transmit(&hspi5, (uint8_t*) &Value, 1, Spi5Timeout);

  /* Check the communication status */
  if(status != HAL_OK)
  {
    /* Re-Initialize the BUS */
    SPI5_Error();
  }
}

/**
  * @brief  SPI5 error treatment function.
  */
static void SPI5_Error(void)
{
  /* De-initialize the SPI communication BUS */
  //HAL_SPI_DeInit(&SpiHandle);

  /* Re- Initialize the SPI communication BUS */
  //SPIx_Init();
}

void LCD_IO_Init(void)
{
  /* Set or Reset the control line */
  HAL_GPIO_WritePin(GPIOC, GPIO_PIN_2, GPIO_PIN_RESET);
  HAL_GPIO_WritePin(GPIOC, GPIO_PIN_2, GPIO_PIN_SET);
}

/**
  * @brief  Writes register value.
  */
void LCD_IO_WriteData(uint16_t RegValue)
{
  /* Set WRX to send data */
  HAL_GPIO_WritePin(GPIOD, GPIO_PIN_13, GPIO_PIN_SET);

  /* Reset LCD control line(/CS) and Send data */
  HAL_GPIO_WritePin(GPIOC, GPIO_PIN_2, GPIO_PIN_RESET);
  SPI5_Write(RegValue);

  /* Deselect: Chip Select high */
  HAL_GPIO_WritePin(GPIOC, GPIO_PIN_2, GPIO_PIN_SET);
}

/**
  * @brief  Writes register address.
  */
void LCD_IO_WriteReg(uint8_t Reg)
{
  /* Reset WRX to send command */
  HAL_GPIO_WritePin(GPIOD, GPIO_PIN_13, GPIO_PIN_RESET);

  /* Reset LCD control line(/CS) and Send command */
  HAL_GPIO_WritePin(GPIOC, GPIO_PIN_2, GPIO_PIN_RESET);
  SPI5_Write(Reg);

  /* Deselect: Chip Select high */
  HAL_GPIO_WritePin(GPIOC, GPIO_PIN_2, GPIO_PIN_SET);
}

/**
  * @brief  Reads register value.
  * @param  RegValue Address of the register to read
  * @param  ReadSize Number of bytes to read
  * @retval Content of the register value
  */
uint32_t LCD_IO_ReadData(uint16_t RegValue, uint8_t ReadSize)
{
  uint32_t readvalue = 0;

  /* Select: Chip Select low */
  HAL_GPIO_WritePin(GPIOC, GPIO_PIN_2, GPIO_PIN_RESET);

  /* Reset WRX to send command */
  HAL_GPIO_WritePin(GPIOD, GPIO_PIN_13, GPIO_PIN_RESET);

  SPI5_Write(RegValue);

  readvalue = SPI5_Read(ReadSize);

  /* Set WRX to send data */
  HAL_GPIO_WritePin(GPIOD, GPIO_PIN_13, GPIO_PIN_SET);

  /* Deselect: Chip Select high */
  HAL_GPIO_WritePin(GPIOC, GPIO_PIN_2, GPIO_PIN_SET);

  return readvalue;
}

/**
  * @brief  Wait for loop in ms.
  * @param  Delay in ms.
  */
void LCD_Delay(uint32_t Delay)
{
  HAL_Delay(Delay);
}

void setPWM(TIM_HandleTypeDef timer, uint32_t channel, uint16_t period,
uint16_t pulse)
{
 HAL_TIM_PWM_Stop(&timer, channel); // stop generation of pwm
 TIM_OC_InitTypeDef sConfigOC;
 timer.Init.Period = period; // set the period duration
 HAL_TIM_PWM_Init(&timer); // reinititialise with new period value

 sConfigOC.OCMode = TIM_OCMODE_PWM1;
 sConfigOC.Pulse = pulse; // set the pulse duration
 sConfigOC.OCPolarity = TIM_OCPOLARITY_HIGH;
 sConfigOC.OCNPolarity = TIM_OCNPOLARITY_HIGH;
 sConfigOC.OCFastMode = TIM_OCFAST_DISABLE;
 sConfigOC.OCIdleState = TIM_OCIDLESTATE_RESET;
 sConfigOC.OCNIdleState = TIM_OCNIDLESTATE_RESET;

 HAL_TIM_PWM_ConfigChannel(&timer, &sConfigOC, channel);
 HAL_TIM_PWM_Start(&timer, channel); // start pwm generation
}

int __io_putchar(int ch)
{

//	 HAL_UART_Transmit(&huart4, (uint8_t *)&ch, 1, 0xFFFF);
//	uint8_t data = "T";
	 uint8_t t = CDC_Transmit_HS((uint8_t *)&ch, 1);
//	 ITM_SendChar(ch);
	 HAL_Delay(1);
	 return ch;
}

void App_Task(void *argument)
{
  /* Infinite loop */
  float temp = 0;

	int heatOn = 0;
	float ie = 0;
	  MX_USB_DEVICE_Init();
  for(;;)
  {
    osDelay(500);

    HAL_GPIO_TogglePin(GPIOG, GPIO_PIN_13);

    uint16_t readvalue;
    HAL_GPIO_WritePin(GPIOE, GPIO_PIN_4, GPIO_PIN_RESET);
    osDelay(1);
    HAL_StatusTypeDef hal_status = HAL_SPI_Receive(&hspi4, (uint8_t*) &readvalue, 1, 10);
    HAL_GPIO_WritePin(GPIOE, GPIO_PIN_4, GPIO_PIN_SET);
    readvalue = readvalue >> 3;

    /* Check the communication status */
    if(hal_status != HAL_OK)
    {
      /* Re-Initialize the BUS */
    	temp = -1;
//    	int status = osMessageQueuePut(TempQueue, &temp, 0, 0);
    }
    else
    {
    	printf("%f;%f;%f\r\n", (float)(current_tick - start_tick)*HAL_GetTickFreq()/1000, temp, temp2);
    	int status = osMessageQueuePut(TempQueue, &temp, 0, 0);

    	if(heatOn)
    	{
    		float consigne = 200.0;

    	/*
    	 * e -> 0 => f_pid -> 0
    	 * e = 80 - 25 = 45
    	 *
    	 *
    	 */
    	const float Kp=6, Ki=0.006, Kd=0;

    	float e = consigne - temp;
    	float de = 0;

    	ie += temp * .5;

    	float f_pid = Kp * e + Ki * ie + Kd * de;

    	float g = f_pid * 400;
    	if (g < 0)
    		g = 0;
    	else if (g > 65535)
    		g = 65535;

//    	printf("%f\r\n", 0.2857 * (current_tick - start_tick)*HAL_GetTickFreq()/1000 + 35);
    	setPWM(htim1, TIM_CHANNEL_2, 65535, (uint16_t)g);
    	}
    }

    uint32_t flag = osEventFlagsWait(msgFlags, MSG_BUTTON_START, osFlagsWaitAny, 0);
    if(flag != osFlagsErrorResource)
    {
    	uint32_t f = flag;
//    	HAL_GPIO_TogglePin(GPIOG, GPIO_PIN_2);
    	heatOn = !heatOn;
    	if(heatOn == 0)
    	{
    		ie = 0;
    		HAL_TIM_PWM_Stop(&htim1, TIM_CHANNEL_2);
    	}
    	else
    	{
    		HAL_TIM_PWM_Start(&htim1, TIM_CHANNEL_2);
    	}
    }

    flag = osEventFlagsWait(msgFlags, MSG_BUTTON_DEVELOP, osFlagsWaitAny, 0);
    if(flag != osFlagsErrorResource)
    {
    	uint32_t f = flag;
    }

  }
}

/* USER CODE END 4 */

__weak void TouchGFX_Task(void *argument)
{
  /* init code for USB_DEVICE */
  MX_USB_DEVICE_Init();
  for(;;)
  {
    osDelay(1);
  }
}

 /**
  * @brief  Period elapsed callback in non blocking mode
  * @note   This function is called  when TIM6 interrupt took place, inside
  * HAL_TIM_IRQHandler(). It makes a direct call to HAL_IncTick() to increment
  * a global variable "uwTick" used as application time base.
  * @param  htim : TIM handle
  * @retval None
  */
void HAL_TIM_PeriodElapsedCallback(TIM_HandleTypeDef *htim)
{
  if (htim->Instance == TIM6) {
    HAL_IncTick();
  }
}

void Error_Handler(void)
{
}

/************************ (C) COPYRIGHT STMicroelectronics *****END OF FILE****/
